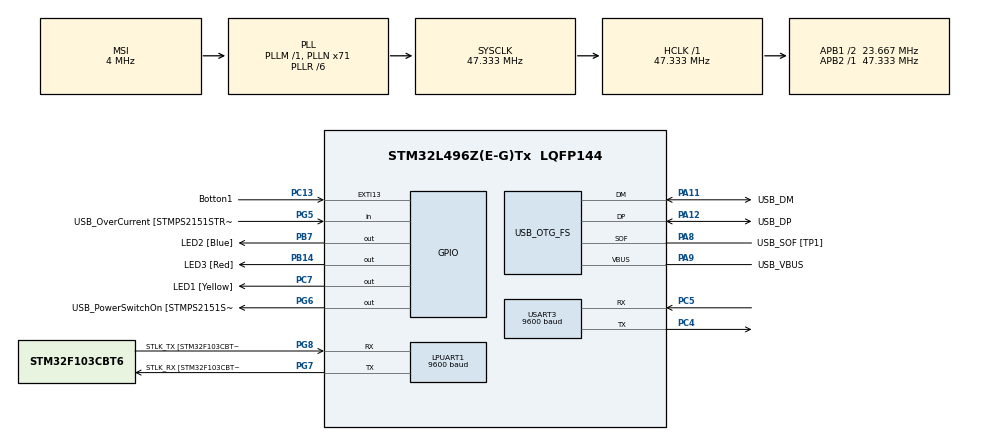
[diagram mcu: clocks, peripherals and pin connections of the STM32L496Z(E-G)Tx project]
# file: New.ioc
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LPUART1.BaudRate=9600
LPUART1.WordLength=UART_WORDLENGTH_8B
Mcu.Family=STM32L4
Mcu.Name=STM32L496Z(E-G)Tx
Mcu.Package=LQFP144
NVIC.LPUART1_IRQn=true\:0\:0\:false\:false\:true\:true
NVIC.PriorityGroup=NVIC_PRIORITYGROUP_4
NVIC.USART3_IRQn=true\:0\:0\:false\:false\:true\:true
PA11.GPIO_Label=USB_DM
PA11.Mode=Device_Only
PA11.Signal=USB_OTG_FS_DM
PA12.GPIO_Label=USB_DP
PA12.Mode=Device_Only
PA12.Signal=USB_OTG_FS_DP
PA13\ (JTMS/SWDIO).GPIO_Label=TMS
PA13\ (JTMS/SWDIO).Mode=Trace_Asynchronous_SW
PA13\ (JTMS/SWDIO).Signal=SYS_JTMS-SWDIO
PA14\ (JTCK/SWCLK).GPIO_Label=TCK
PA14\ (JTCK/SWCLK).Mode=Trace_Asynchronous_SW
PA14\ (JTCK/SWCLK).Signal=SYS_JTCK-SWCLK
PA8.GPIO_Label=USB_SOF [TP1]
PA8.Mode=Activate_SOF_FS
PA8.Signal=USB_OTG_FS_SOF
PA9.GPIO_Label=USB_VBUS
PA9.Mode=Activate_VBUS
PA9.Signal=USB_OTG_FS_VBUS
PB14.GPIO_Label=LED3 [Red]
PB14.Signal=GPIO_Output
PB3\ (JTDO/TRACESWO).GPIO_Label=SWO
PB3\ (JTDO/TRACESWO).Mode=Trace_Asynchronous_SW
PB3\ (JTDO/TRACESWO).Signal=SYS_JTDO-SWO
PB7.GPIO_Label=LED2 [Blue]
PB7.Signal=GPIO_Output
PC13.GPIO_Label=Botton1
PC13.Signal=GPXTI13
PC14-OSC32_IN\ (PC14).Mode=LSE-External-Oscillator
PC14-OSC32_IN\ (PC14).Signal=RCC_OSC32_IN
PC15-OSC32_OUT\ (PC15).Mode=LSE-External-Oscillator
PC15-OSC32_OUT\ (PC15).Signal=RCC_OSC32_OUT
PC4.Mode=Asynchronous
PC4.Signal=USART3_TX
PC5.Mode=Asynchronous
PC5.Signal=USART3_RX
PC7.GPIO_Label=LED1 [Yellow]
PC7.PinState=GPIO_PIN_SET
PC7.Signal=GPIO_Output
PG5.GPIO_Label=USB_OverCurrent [STMPS2151STR_FAULT]
PG5.Signal=GPIO_Input
PG6.GPIO_Label=USB_PowerSwitchOn [STMPS2151STR_EN]
PG6.Signal=GPIO_Output
PG7.GPIO_Label=STLK_RX [STM32F103CBT6_PA3]
PG7.Mode=Asynchronous
PG7.Signal=LPUART1_TX
PG8.GPIO_Label=STLK_TX [STM32F103CBT6_PA2]
PG8.Mode=Asynchronous
PG8.Signal=LPUART1_RX
ProjectManager.HeapSize=0x200
ProjectManager.StackSize=0x400
ProjectManager.TargetToolchain=MDK-ARM V5
RCC.48MHZClocksFreq_Value=24000000
RCC.ADCFreq_Value=48000000
RCC.AHBFreq_Value=47333333.333333336
RCC.APB1CLKDivider=RCC_HCLK_DIV2
RCC.APB1Freq_Value=23666666.666666668
RCC.APB1TimFreq_Value=47333333.333333336
RCC.APB2Freq_Value=47333333.333333336
RCC.APB2TimFreq_Value=47333333.333333336
RCC.CortexFreq_Value=47333333.333333336
RCC.HCLKFreq_Value=47333333.333333336
RCC.HSE_VALUE=8000000
RCC.HSI48_VALUE=48000000
RCC.HSI_VALUE=16000000
RCC.MSI_VALUE=4000000
RCC.PLLMUL=RCC_PLL_MUL9
RCC.PLLN=71
RCC.PLLR=RCC_PLLR_DIV6
RCC.PLLSAI1N=24
RCC.PRESCALERUSB=RCC_USBCLKSOURCE_PLL_DIV1_5
RCC.SYSCLKFreq_VALUE=47333333.333333336
RCC.SYSCLKSource=RCC_SYSCLKSOURCE_PLLCLK
RCC.SYSCLKSourceVirtual=RCC_SYSCLKSOURCE_PLLCLK
RCC.USBFreq_Value=48000000
RCC.VCOOutputFreq_Value=284000000
USART3.BaudRate=9600
USART3.VirtualMode-Asynchronous=VM_ASYNC
USB_OTG_FS.VirtualMode=Device_Only
board=NUCLEO-L496ZG

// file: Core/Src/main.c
/**
  ******************************************************************************
  * @file           : main.c
  * @brief          : Main program body
  ******************************************************************************
  ** This notice applies to any and all portions of this file
  * that are not between comment pairs USER CODE BEGIN and
  * USER CODE END. Other portions of this file, whether
  * inserted by the user or by software development tools
  * are owned by their respective copyright owners.
  *
  * COPYRIGHT(c) 2018 STMicroelectronics
  *
  * Redistribution and use in source and binary forms, with or without modification,
  * are permitted provided that the following conditions are met:
  *   1. Redistributions of source code must retain the above copyright notice,
  *      this list of conditions and the following disclaimer.
  *   2. Redistributions in binary form must reproduce the above copyright notice,
  *      this list of conditions and the following disclaimer in the documentation
  *      and/or other materials provided with the distribution.
  *   3. Neither the name of STMicroelectronics nor the names of its contributors
  *      may be used to endorse or promote products derived from this software
  *      without specific prior written permission.
  *
  * THIS SOFTWARE IS PROVIDED BY THE COPYRIGHT HOLDERS AND CONTRIBUTORS "AS IS"
  * AND ANY EXPRESS OR IMPLIED WARRANTIES, INCLUDING, BUT NOT LIMITED TO, THE
  * IMPLIED WARRANTIES OF MERCHANTABILITY AND FITNESS FOR A PARTICULAR PURPOSE ARE
  * DISCLAIMED. IN NO EVENT SHALL THE COPYRIGHT HOLDER OR CONTRIBUTORS BE LIABLE
  * FOR ANY DIRECT, INDIRECT, INCIDENTAL, SPECIAL, EXEMPLARY, OR CONSEQUENTIAL
  * DAMAGES (INCLUDING, BUT NOT LIMITED TO, PROCUREMENT OF SUBSTITUTE GOODS OR
  * SERVICES; LOSS OF USE, DATA, OR PROFITS; OR BUSINESS INTERRUPTION) HOWEVER
  * CAUSED AND ON ANY THEORY OF LIABILITY, WHETHER IN CONTRACT, STRICT LIABILITY,
  * OR TORT (INCLUDING NEGLIGENCE OR OTHERWISE) ARISING IN ANY WAY OUT OF THE USE
  * OF THIS SOFTWARE, EVEN IF ADVISED OF THE POSSIBILITY OF SUCH DAMAGE.
  *
  ******************************************************************************
  */
#include "main.h"
#include "stm32l4xx_hal.h"
#include "usart.h"
#include "usb_otg.h"
#include "gpio.h"
#include "stdint.h"

/* USER CODE BEGIN PV */
/* Private variables ---------------------------------------------------------*/

/* USER CODE END PV */

void SystemClock_Config(void);

/* USER CODE BEGIN PFP */
/* Private function prototypes -----------------------------------------------*/

/* USER CODE END PFP */

int main(void)
{

	/* MCU Configuration----------------------------------------------------------*/

	/* Reset of all peripherals, Initializes the Flash interface and the Systick. */
	HAL_Init();

	/* Configure the system clock */
	SystemClock_Config();

	/* Initialize all configured peripherals */
	MX_GPIO_Init();
	MX_LPUART1_UART_Init();
	MX_USB_OTG_FS_PCD_Init();
	MX_USART3_UART_Init();
	/* USER CODE BEGIN 2 */
	HAL_UART_Receive_IT(MY_UART, aRxBuffer, 1);
	/* USER CODE END 2 */

	/* Infinite loop */
	while (1)
	{

		/* USER CODE BEGIN 3 */
		HAL_Delay(1000);
		printf("12345���룬���Ҳ�������\n");	// ��������

//		HAL_Delay
	}
	/* USER CODE END 3 */

}

void SystemClock_Config(void)
{

	RCC_OscInitTypeDef RCC_OscInitStruct;
	RCC_ClkInitTypeDef RCC_ClkInitStruct;
	RCC_PeriphCLKInitTypeDef PeriphClkInit;

	/**Configure LSE Drive Capability
	*/
	HAL_PWR_EnableBkUpAccess();

	__HAL_RCC_LSEDRIVE_CONFIG(RCC_LSEDRIVE_LOW);

	/**Initializes the CPU, AHB and APB busses clocks
	*/
	RCC_OscInitStruct.OscillatorType = RCC_OSCILLATORTYPE_LSE|RCC_OSCILLATORTYPE_MSI;
	RCC_OscInitStruct.LSEState = RCC_LSE_ON;
	RCC_OscInitStruct.MSIState = RCC_MSI_ON;
	RCC_OscInitStruct.MSICalibrationValue = 0;
	RCC_OscInitStruct.MSIClockRange = RCC_MSIRANGE_6;
	RCC_OscInitStruct.PLL.PLLState = RCC_PLL_ON;
	RCC_OscInitStruct.PLL.PLLSource = RCC_PLLSOURCE_MSI;
	RCC_OscInitStruct.PLL.PLLM = 1;
	RCC_OscInitStruct.PLL.PLLN = 71;
	RCC_OscInitStruct.PLL.PLLP = RCC_PLLP_DIV2;
	RCC_OscInitStruct.PLL.PLLQ = RCC_PLLQ_DIV2;
	RCC_OscInitStruct.PLL.PLLR = RCC_PLLR_DIV6;
	if (HAL_RCC_OscConfig(&RCC_OscInitStruct) != HAL_OK)
	{
		_Error_Handler(__FILE__, __LINE__);
	}

	/**Initializes the CPU, AHB and APB busses clocks
	*/
	RCC_ClkInitStruct.ClockType = RCC_CLOCKTYPE_HCLK|RCC_CLOCKTYPE_SYSCLK
	                              |RCC_CLOCKTYPE_PCLK1|RCC_CLOCKTYPE_PCLK2;
	RCC_ClkInitStruct.SYSCLKSource = RCC_SYSCLKSOURCE_PLLCLK;
	RCC_ClkInitStruct.AHBCLKDivider = RCC_SYSCLK_DIV1;
	RCC_ClkInitStruct.APB1CLKDivider = RCC_HCLK_DIV2;
	RCC_ClkInitStruct.APB2CLKDivider = RCC_HCLK_DIV1;

	if (HAL_RCC_ClockConfig(&RCC_ClkInitStruct, FLASH_LATENCY_2) != HAL_OK)
	{
		_Error_Handler(__FILE__, __LINE__);
	}

	PeriphClkInit.PeriphClockSelection = RCC_PERIPHCLK_USART3|RCC_PERIPHCLK_LPUART1
	                                     |RCC_PERIPHCLK_USB;
	PeriphClkInit.Usart3ClockSelection = RCC_USART3CLKSOURCE_PCLK1;
	PeriphClkInit.Lpuart1ClockSelection = RCC_LPUART1CLKSOURCE_PCLK1;
	PeriphClkInit.UsbClockSelection = RCC_USBCLKSOURCE_PLLSAI1;
	PeriphClkInit.PLLSAI1.PLLSAI1Source = RCC_PLLSOURCE_MSI;
	PeriphClkInit.PLLSAI1.PLLSAI1M = 1;
	PeriphClkInit.PLLSAI1.PLLSAI1N = 24;
	PeriphClkInit.PLLSAI1.PLLSAI1P = RCC_PLLP_DIV2;
	PeriphClkInit.PLLSAI1.PLLSAI1Q = RCC_PLLQ_DIV2;
	PeriphClkInit.PLLSAI1.PLLSAI1R = RCC_PLLR_DIV2;
	PeriphClkInit.PLLSAI1.PLLSAI1ClockOut = RCC_PLLSAI1_48M2CLK;
	if (HAL_RCCEx_PeriphCLKConfig(&PeriphClkInit) != HAL_OK)
	{
		_Error_Handler(__FILE__, __LINE__);
	}

	/**Configure the main internal regulator output voltage
	*/
	if (HAL_PWREx_ControlVoltageScaling(PWR_REGULATOR_VOLTAGE_SCALE1) != HAL_OK)
	{
		_Error_Handler(__FILE__, __LINE__);
	}

	/**Configure the Systick interrupt time
	*/
	HAL_SYSTICK_Config(HAL_RCC_GetHCLKFreq()/1000);

	/**Configure the Systick
	*/
	HAL_SYSTICK_CLKSourceConfig(SYSTICK_CLKSOURCE_HCLK);

	/**Enable MSI Auto calibration
	*/
	HAL_RCCEx_EnableMSIPLLMode();

	/* SysTick_IRQn interrupt configuration */
	HAL_NVIC_SetPriority(SysTick_IRQn, 0, 0);
}

/* USER CODE BEGIN 4 */
void HAL_UART_RxCpltCallback(UART_HandleTypeDef *huart)
{
	if (huart->Instance == LPUART1)
	{
		HAL_UART_Transmit(MY_UART, aRxBuffer, 1, 0xffff);
	}
	if (huart->Instance == USART3)
	{
		HAL_UART_Transmit(MY_UART, aRxBuffer, 1, 0xffff);
	}
}

/* USER CODE END 4 */

void _Error_Handler(char *file, int line)
{
	while(1)
	{
	}
}

/************************ (C) COPYRIGHT STMicroelectronics *****END OF FILE****/
